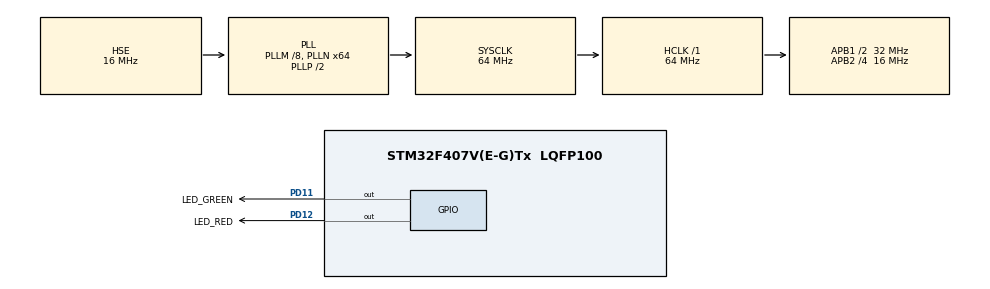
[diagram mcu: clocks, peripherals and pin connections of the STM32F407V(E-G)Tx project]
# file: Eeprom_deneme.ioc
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Mcu.Family=STM32F4
Mcu.Name=STM32F407V(E-G)Tx
Mcu.Package=LQFP100
NVIC.PriorityGroup=NVIC_PRIORITYGROUP_4
PD11.GPIO_Label=LED_GREEN
PD11.Signal=GPIO_Output
PD12.GPIO_Label=LED_RED
PD12.Signal=GPIO_Output
PH0-OSC_IN.Mode=HSE-External-Oscillator
PH0-OSC_IN.Signal=RCC_OSC_IN
PH1-OSC_OUT.Mode=HSE-External-Oscillator
PH1-OSC_OUT.Signal=RCC_OSC_OUT
ProjectManager.HeapSize=0x200
ProjectManager.StackSize=0x400
ProjectManager.TargetToolchain=STM32CubeIDE
RCC.48MHZClocksFreq_Value=32000000
RCC.AHBFreq_Value=64000000
RCC.APB1CLKDivider=RCC_HCLK_DIV2
RCC.APB1Freq_Value=32000000
RCC.APB1TimFreq_Value=64000000
RCC.APB2CLKDivider=RCC_HCLK_DIV4
RCC.APB2Freq_Value=16000000
RCC.APB2TimFreq_Value=32000000
RCC.CortexFreq_Value=64000000
RCC.HCLKFreq_Value=64000000
RCC.HSE_VALUE=16000000
RCC.HSI_VALUE=16000000
RCC.LSE_VALUE=32768
RCC.PLLM=8
RCC.PLLN=64
RCC.PLLSourceVirtual=RCC_PLLSOURCE_HSE
RCC.SYSCLKFreq_VALUE=64000000
RCC.SYSCLKSource=RCC_SYSCLKSOURCE_PLLCLK
RCC.VCOOutputFreq_Value=128000000
board=custom

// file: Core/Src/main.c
/* USER CODE BEGIN Header */
/**
 ******************************************************************************
 * @file           : main.c
 * @brief          : Main program body
 ******************************************************************************
 * @attention
 *
 * Copyright (c) 2022 STMicroelectronics.
 * All rights reserved.
 *
 * This software is licensed under terms that can be found in the LICENSE file
 * in the root directory of this software component.
 * If no LICENSE file comes with this software, it is provided AS-IS.
 *
 ******************************************************************************
 */
/* USER CODE END Header */
#include "main.h"

/* USER CODE BEGIN Includes */
#include "eeprom.h"
/* USER CODE END Includes */

/* USER CODE BEGIN PV */
uint16_t VirtAddVarTab[NB_OF_VAR] = { 0x5555, 0x6666, 0x7777 };
uint16_t VarDataTab[NB_OF_VAR] = { 0, 0, 0 };
uint16_t VarValue, VarDataTmp = 0;
/* USER CODE END PV */

void SystemClock_Config(void);
static void MX_GPIO_Init(void);

int main(void) {

	/* MCU Configuration--------------------------------------------------------*/

	/* Reset of all peripherals, Initializes the Flash interface and the Systick. */
	HAL_Init();

	/* Configure the system clock */
	SystemClock_Config();

	/* Initialize all configured peripherals */
	MX_GPIO_Init();
	/* USER CODE BEGIN 2 */

	/* Unlock the Flash Program Erase controller */
	HAL_FLASH_Unlock();

	/* EEPROM Init */
	if (EE_Init() != EE_OK) {
		Error_Handler();
	}

	/* --- Store successively many values of the three variables in the EEPROM ---*/
	/* Store 0x1000 values of Variable1 in EEPROM */
	for (VarValue = 1; VarValue <= 0x1; VarValue++) {
		/* Sequence 1 */
		if ((EE_WriteVariable(VirtAddVarTab[0], VarValue)) != HAL_OK) {
			Error_Handler();
		}
		if ((EE_ReadVariable(VirtAddVarTab[0], &VarDataTab[0])) != HAL_OK) {
			Error_Handler();
		}
		if (VarValue != VarDataTab[0]) {
			Error_Handler();
		}

		/* Sequence 2 */
		if (EE_WriteVariable(VirtAddVarTab[1], ~VarValue) != HAL_OK) {
			Error_Handler();
		}
		if (EE_ReadVariable(VirtAddVarTab[1], &VarDataTab[1]) != HAL_OK) {
			Error_Handler();
		}
		if (((uint16_t) ~VarValue) != VarDataTab[1]) {
			Error_Handler();
		}

		/* Sequence 3 */
		if (EE_WriteVariable(VirtAddVarTab[2], VarValue << 1) != HAL_OK) {
			Error_Handler();
		}
		if (EE_ReadVariable(VirtAddVarTab[2], &VarDataTab[2]) != HAL_OK) {
			Error_Handler();
		}
		if ((VarValue << 1) != VarDataTab[2]) {
			Error_Handler();
		}
	}
//
//	/* Store 0x2000 values of Variable2 in EEPROM */
//	for (VarValue = 1; VarValue <= 0x2; VarValue++) {
//		if (EE_WriteVariable(VirtAddVarTab[1], VarValue) != HAL_OK) {
//			Error_Handler();
//		}
//		if (EE_ReadVariable(VirtAddVarTab[1], &VarDataTab[1]) != HAL_OK) {
//			Error_Handler();
//		}
//		if (VarValue != VarDataTab[1]) {
//			Error_Handler();
//		}
//	}
//
//	/* read the last stored variables data*/
//	if (EE_ReadVariable(VirtAddVarTab[0], &VarDataTmp) != HAL_OK) {
//		Error_Handler();
//	}
//	if (VarDataTmp != VarDataTab[0]) {
//		Error_Handler();
//	}
//
//	if (EE_ReadVariable(VirtAddVarTab[1], &VarDataTmp) != HAL_OK) {
//		Error_Handler();
//	}
//	if (VarDataTmp != VarDataTab[1]) {
//		Error_Handler();
//	}
//
//	if (EE_ReadVariable(VirtAddVarTab[2], &VarDataTmp) != HAL_OK) {
//		Error_Handler();
//	}
//	if (VarDataTmp != VarDataTab[2]) {
//		Error_Handler();
//	}
//
//	/* Store 0x3000 values of Variable3 in EEPROM */
//	for (VarValue = 1; VarValue <= 0x3; VarValue++) {
//		if (EE_WriteVariable(VirtAddVarTab[2], VarValue) != HAL_OK) {
//			Error_Handler();
//		}
//		if (EE_ReadVariable(VirtAddVarTab[2], &VarDataTab[2]) != HAL_OK) {
//			Error_Handler();
//		}
//		if (VarValue != VarDataTab[2]) {
//			Error_Handler();
//		}
//	}
//
//	/* read the last stored variables data*/
//	if (EE_ReadVariable(VirtAddVarTab[0], &VarDataTmp) != HAL_OK) {
//		Error_Handler();
//	}
//	if (VarDataTmp != VarDataTab[0]) {
//		Error_Handler();
//	}
//
//	if (EE_ReadVariable(VirtAddVarTab[1], &VarDataTmp) != HAL_OK) {
//		Error_Handler();
//	}
//	if (VarDataTmp != VarDataTab[1]) {
//		Error_Handler();
//	}
//
//	if (EE_ReadVariable(VirtAddVarTab[2], &VarDataTmp) != HAL_OK) {
//		Error_Handler();
//	}
//	if (VarDataTmp != VarDataTab[2]) {
//		Error_Handler();
//	}

	/* USER CODE END 2 */

	/* Infinite loop */
	while (1) {

		/* USER CODE BEGIN 3 */
		HAL_GPIO_TogglePin(LED_GREEN_GPIO_Port, LED_GREEN_Pin);
		HAL_Delay(500);
	}
	/* USER CODE END 3 */
}

void SystemClock_Config(void) {
	RCC_OscInitTypeDef RCC_OscInitStruct = { 0 };
	RCC_ClkInitTypeDef RCC_ClkInitStruct = { 0 };

	/** Configure the main internal regulator output voltage
	 */
	__HAL_RCC_PWR_CLK_ENABLE();
	__HAL_PWR_VOLTAGESCALING_CONFIG(PWR_REGULATOR_VOLTAGE_SCALE1);

	/** Initializes the RCC Oscillators according to the specified parameters
	 * in the RCC_OscInitTypeDef structure.
	 */
	RCC_OscInitStruct.OscillatorType = RCC_OSCILLATORTYPE_HSE;
	RCC_OscInitStruct.HSEState = RCC_HSE_ON;
	RCC_OscInitStruct.PLL.PLLState = RCC_PLL_ON;
	RCC_OscInitStruct.PLL.PLLSource = RCC_PLLSOURCE_HSE;
	RCC_OscInitStruct.PLL.PLLM = 8;
	RCC_OscInitStruct.PLL.PLLN = 64;
	RCC_OscInitStruct.PLL.PLLP = RCC_PLLP_DIV2;
	RCC_OscInitStruct.PLL.PLLQ = 4;
	if (HAL_RCC_OscConfig(&RCC_OscInitStruct) != HAL_OK) {
		Error_Handler();
	}

	/** Initializes the CPU, AHB and APB buses clocks
	 */
	RCC_ClkInitStruct.ClockType = RCC_CLOCKTYPE_HCLK | RCC_CLOCKTYPE_SYSCLK
			| RCC_CLOCKTYPE_PCLK1 | RCC_CLOCKTYPE_PCLK2;
	RCC_ClkInitStruct.SYSCLKSource = RCC_SYSCLKSOURCE_PLLCLK;
	RCC_ClkInitStruct.AHBCLKDivider = RCC_SYSCLK_DIV1;
	RCC_ClkInitStruct.APB1CLKDivider = RCC_HCLK_DIV2;
	RCC_ClkInitStruct.APB2CLKDivider = RCC_HCLK_DIV4;

	if (HAL_RCC_ClockConfig(&RCC_ClkInitStruct, FLASH_LATENCY_2) != HAL_OK) {
		Error_Handler();
	}
}

static void MX_GPIO_Init(void) {
	GPIO_InitTypeDef GPIO_InitStruct = { 0 };

	/* GPIO Ports Clock Enable */
	__HAL_RCC_GPIOH_CLK_ENABLE();
	__HAL_RCC_GPIOD_CLK_ENABLE();

	/*Configure GPIO pin Output Level */
	HAL_GPIO_WritePin(GPIOD, LED_GREEN_Pin | LED_RED_Pin, GPIO_PIN_RESET);

	/*Configure GPIO pins : LED_GREEN_Pin LED_RED_Pin */
	GPIO_InitStruct.Pin = LED_GREEN_Pin | LED_RED_Pin;
	GPIO_InitStruct.Mode = GPIO_MODE_OUTPUT_PP;
	GPIO_InitStruct.Pull = GPIO_NOPULL;
	GPIO_InitStruct.Speed = GPIO_SPEED_FREQ_LOW;
	HAL_GPIO_Init(GPIOD, &GPIO_InitStruct);

}

void Error_Handler(void) {
	/* USER CODE BEGIN Error_Handler_Debug */
	/* User can add his own implementation to report the HAL error return state */
	__disable_irq();
	while (1) {
		/* Toggle LED fast */
		HAL_GPIO_TogglePin(LED_RED_GPIO_Port, LED_RED_Pin);
		HAL_Delay(100);

	}
	/* USER CODE END Error_Handler_Debug */
}
